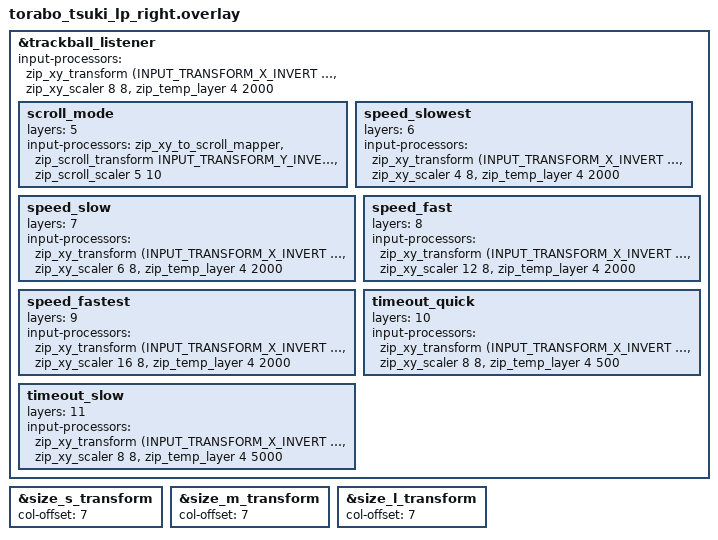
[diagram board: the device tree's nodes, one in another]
#include "torabo_tsuki_lp.dtsi"
#include <input/processors.dtsi>
#include <dt-bindings/zmk/input_transform.h>

&trackball_listener {
    input-processors = <
        &zip_xy_transform (INPUT_TRANSFORM_X_INVERT | INPUT_TRANSFORM_Y_INVERT)
        &zip_xy_scaler 8 8
        &zip_temp_layer 4 2000
    >;

    scroll_mode {
        layers = <5>;
        input-processors = <
            &zip_xy_to_scroll_mapper
            &zip_scroll_transform INPUT_TRANSFORM_Y_INVERT
            &zip_scroll_scaler 5 10
        >;
    };

    /* Speed Level 1 (Slowest): 0.5x speed - Layer 6 */
    speed_slowest {
        layers = <6>;
        input-processors = <
            &zip_xy_transform (INPUT_TRANSFORM_X_INVERT | INPUT_TRANSFORM_Y_INVERT)
            &zip_xy_scaler 4 8
            &zip_temp_layer 4 2000
        >;
    };

    /* Speed Level 2 (Slow): 0.75x speed - Layer 7 */
    speed_slow {
        layers = <7>;
        input-processors = <
            &zip_xy_transform (INPUT_TRANSFORM_X_INVERT | INPUT_TRANSFORM_Y_INVERT)
            &zip_xy_scaler 6 8
            &zip_temp_layer 4 2000
        >;
    };

    /* Speed Level 4 (Fast): 1.5x speed - Layer 8 */
    speed_fast {
        layers = <8>;
        input-processors = <
            &zip_xy_transform (INPUT_TRANSFORM_X_INVERT | INPUT_TRANSFORM_Y_INVERT)
            &zip_xy_scaler 12 8
            &zip_temp_layer 4 2000
        >;
    };

    /* Speed Level 5 (Fastest): 2x speed - Layer 9 */
    speed_fastest {
        layers = <9>;
        input-processors = <
            &zip_xy_transform (INPUT_TRANSFORM_X_INVERT | INPUT_TRANSFORM_Y_INVERT)
            &zip_xy_scaler 16 8
            &zip_temp_layer 4 2000
        >;
    };

    /* Quick Timeout (500ms) - Layer 10 */
    timeout_quick {
        layers = <10>;
        input-processors = <
            &zip_xy_transform (INPUT_TRANSFORM_X_INVERT | INPUT_TRANSFORM_Y_INVERT)
            &zip_xy_scaler 8 8
            &zip_temp_layer 4 500
        >;
    };

    /* Slow Timeout (5000ms) - Layer 11 */
    timeout_slow {
        layers = <11>;
        input-processors = <
            &zip_xy_transform (INPUT_TRANSFORM_X_INVERT | INPUT_TRANSFORM_Y_INVERT)
            &zip_xy_scaler 8 8
            &zip_temp_layer 4 5000
        >;
    };
};

&size_s_transform {
    col-offset = <7>;
};

&size_m_transform {
    col-offset = <7>;
};

&size_l_transform {
    col-offset = <7>;
};
